# BS2X register map
File version: 0.1
CPU: other r0p0, little endian, MPU, FPU, 3 interrupt priority bits
Registers are 32-bit, read-write, reset 0x0 unless marked. A register's access mark holds for its fields unless they carry their own. Offsets are from the block's base; [hi:lo] are bit positions.

## USB — USB 2.0 OTG controller (Synopsys DWC OTG, device-controller base)
Base 0x58000000
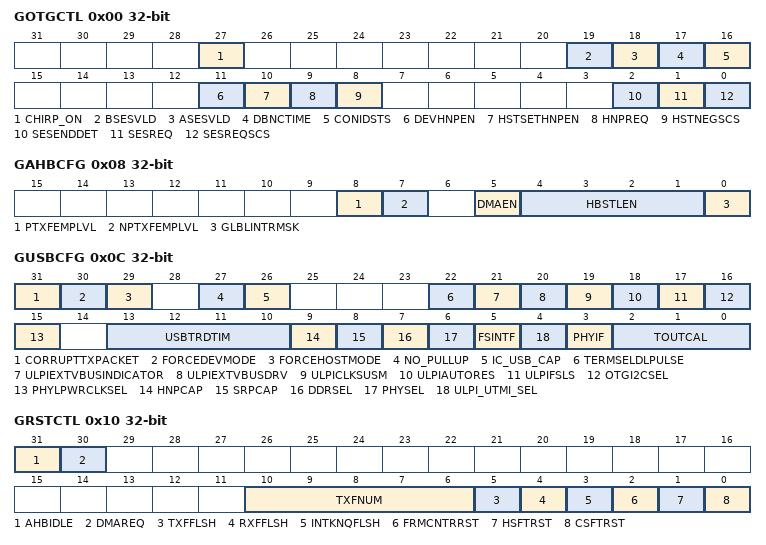
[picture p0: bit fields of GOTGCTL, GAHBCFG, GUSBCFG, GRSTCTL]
0x00 GOTGCTL — DOTG_GOTGCTL
  [27] CHIRP_ON, [19] BSESVLD, [18] ASESVLD, [17] DBNCTIME, [16] CONIDSTS, [11] DEVHNPEN, [10] HSTSETHNPEN, [9] HNPREQ, [8] HSTNEGSCS, [2] SESENDDET, [1] SESREQ, [0] SESREQSCS
0x04 GOTGINT — DOTG_GOTGINT
0x08 GAHBCFG — DOTG_GAHBCFG
  [8] PTXFEMPLVL, [7] NPTXFEMPLVL, [5] DMAEN, [4:1] HBSTLEN, [0] GLBLINTRMSK
0x0C GUSBCFG — DOTG_GUSBCFG
  [31] CORRUPTTXPACKET, [30] FORCEDEVMODE, [29] FORCEHOSTMODE, [27] NO_PULLUP, [26] IC_USB_CAP, [22] TERMSELDLPULSE, [21] ULPIEXTVBUSINDICATOR, [20] ULPIEXTVBUSDRV, [19] ULPICLKSUSM, [18] ULPIAUTORES, [17] ULPIFSLS, [16] OTGI2CSEL, [15] PHYLPWRCLKSEL, [13:10] USBTRDTIM, [9] HNPCAP, [8] SRPCAP, [7] DDRSEL, [6] PHYSEL, [5] FSINTF, [4] ULPI_UTMI_SEL, [3] PHYIF, [2:0] TOUTCAL
0x10 GRSTCTL — DOTG_GRSTCTL
  [31] AHBIDLE, [30] DMAREQ, [10:6] TXFNUM, [5] TXFFLSH, [4] RXFFLSH, [3] INTKNQFLSH, [2] FRMCNTRRST, [1] HSFTRST, [0] CSFTRST
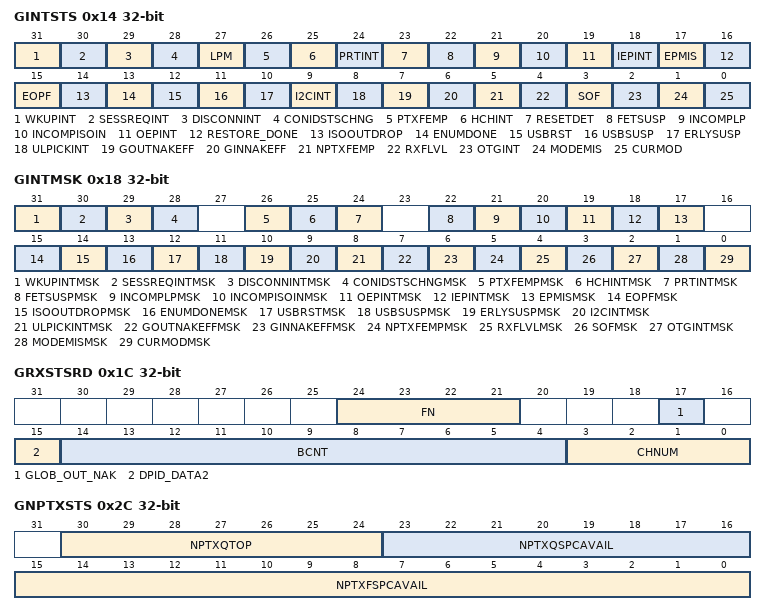
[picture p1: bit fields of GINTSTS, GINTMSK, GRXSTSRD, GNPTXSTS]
0x14 GINTSTS — DOTG_GINTSTS
  [31] WKUPINT, [30] SESSREQINT, [29] DISCONNINT, [28] CONIDSTSCHNG, [27] LPM, [26] PTXFEMP, [25] HCHINT, [24] PRTINT, [23] RESETDET, [22] FETSUSP, [21] INCOMPLP, [20] INCOMPISOIN, [19] OEPINT, [18] IEPINT, [17] EPMIS, [16] RESTORE_DONE, [15] EOPF, [14] ISOOUTDROP, [13] ENUMDONE, [12] USBRST, [11] USBSUSP, [10] ERLYSUSP, [9] I2CINT, [8] ULPICKINT, [7] GOUTNAKEFF, [6] GINNAKEFF, [5] NPTXFEMP, [4] RXFLVL, [3] SOF, [2] OTGINT, [1] MODEMIS, [0] CURMOD
0x18 GINTMSK — DOTG_GINTMSK
  [31] WKUPINTMSK, [30] SESSREQINTMSK, [29] DISCONNINTMSK, [28] CONIDSTSCHNGMSK, [26] PTXFEMPMSK, [25] HCHINTMSK, [24] PRTINTMSK, [22] FETSUSPMSK, [21] INCOMPLPMSK, [20] INCOMPISOINMSK, [19] OEPINTMSK, [18] IEPINTMSK, [17] EPMISMSK, [15] EOPFMSK, [14] ISOOUTDROPMSK, [13] ENUMDONEMSK, [12] USBRSTMSK, [11] USBSUSPMSK, [10] ERLYSUSPMSK, [9] I2CINTMSK, [8] ULPICKINTMSK, [7] GOUTNAKEFFMSK, [6] GINNAKEFFMSK, [5] NPTXFEMPMSK, [4] RXFLVLMSK, [3] SOFMSK, [2] OTGINTMSK, [1] MODEMISMSK, [0] CURMODMSK
0x1C GRXSTSRD — DOTG_GRXSTSRD
  [24:21] FN, [17] GLOB_OUT_NAK, [15] DPID_DATA2, [14:4] BCNT, [3:0] CHNUM
0x20 GRXSTSPD — DOTG_GRXSTSPD
0x24 GRXFSIZ — DOTG_GRXFSIZ
  [15:0] RXFDEP
0x28 GNPTXFSIZ — DOTG_GNPTXFSIZ
  [15:0] NPTXFDEP
0x2C GNPTXSTS — DOTG_GNPTXSTS
  [30:24] NPTXQTOP, [23:16] NPTXQSPCAVAIL, [15:0] NPTXFSPCAVAIL
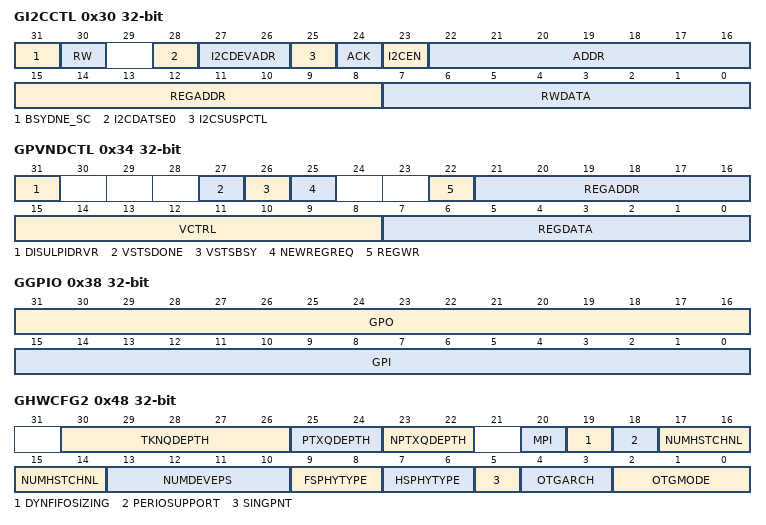
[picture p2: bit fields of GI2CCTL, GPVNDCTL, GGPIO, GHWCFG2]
0x30 GI2CCTL — DOTG_GI2CCTL
  [31] BSYDNE_SC, [30] RW, [28] I2CDATSE0, [27:26] I2CDEVADR, [25] I2CSUSPCTL, [24] ACK, [23] I2CEN, [22:16] ADDR, [15:8] REGADDR, [7:0] RWDATA
0x34 GPVNDCTL — DOTG_GPVNDCTL
  [31] DISULPIDRVR, [27] VSTSDONE, [26] VSTSBSY, [25] NEWREGREQ, [22] REGWR, [21:16] REGADDR, [15:8] VCTRL, [7:0] REGDATA
0x38 GGPIO — DOTG_GGPIO
  [31:16] GPO, [15:0] GPI
0x3C GUID — DOTG_GUID
0x40 GSNPSID — DOTG_GSNPSID
0x44 GHWCFG1 — DOTG_GHWCFG1
0x48 GHWCFG2 — DOTG_GHWCFG2
  [30:26] TKNQDEPTH, [25:24] PTXQDEPTH, [23:22] NPTXQDEPTH, [20] MPI, [19] DYNFIFOSIZING, [18] PERIOSUPPORT, [17:14] NUMHSTCHNL, [13:10] NUMDEVEPS, [9:8] FSPHYTYPE, [7:6] HSPHYTYPE, [5] SINGPNT, [4:3] OTGARCH, [2:0] OTGMODE
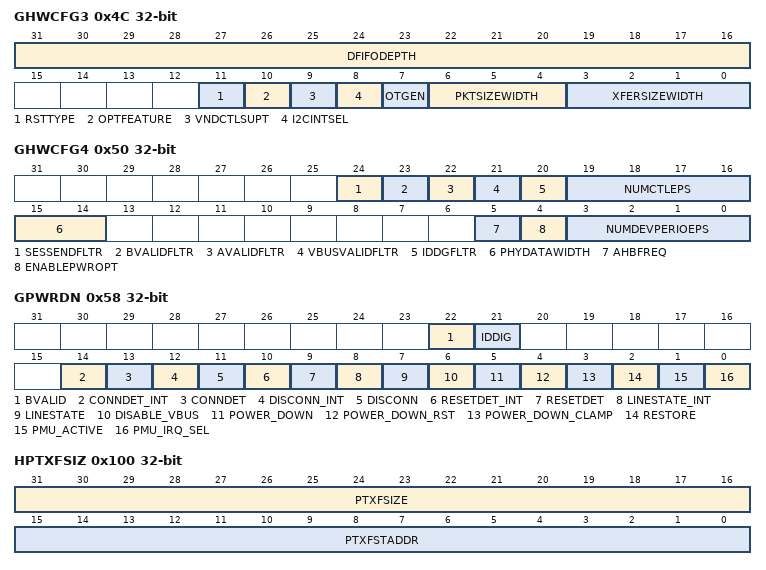
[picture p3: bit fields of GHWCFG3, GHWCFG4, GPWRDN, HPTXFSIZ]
0x4C GHWCFG3 — DOTG_GHWCFG3
  [31:16] DFIFODEPTH, [11] RSTTYPE, [10] OPTFEATURE, [9] VNDCTLSUPT, [8] I2CINTSEL, [7] OTGEN, [6:4] PKTSIZEWIDTH, [3:0] XFERSIZEWIDTH
0x50 GHWCFG4 — DOTG_GHWCFG4
  [24] SESSENDFLTR, [23] BVALIDFLTR, [22] AVALIDFLTR, [21] VBUSVALIDFLTR, [20] IDDGFLTR, [19:16] NUMCTLEPS, [15:14] PHYDATAWIDTH, [5] AHBFREQ, [4] ENABLEPWROPT, [3:0] NUMDEVPERIOEPS
0x54 GLPMCFG — DOTG_GLPMCFG
  [30] HSIC_CONN
0x58 GPWRDN — DOTG_GPWRDN
  [22] BVALID, [21] IDDIG, [14] CONNDET_INT, [13] CONNDET, [12] DISCONN_INT, [11] DISCONN, [10] RESETDET_INT, [9] RESETDET, [8] LINESTATE_INT, [7] LINESTATE, [6] DISABLE_VBUS, [5] POWER_DOWN, [4] POWER_DOWN_RST, [3] POWER_DOWN_CLAMP, [2] RESTORE, [1] PMU_ACTIVE, [0] PMU_IRQ_SEL
0x5C GDFIFOCFG — DOTG_GDFIFOCFG
0x60 GADPCTL — DOTG_GADPCTL
0x100 HPTXFSIZ — DOTG_HPTXFSIZ
  [31:16] PTXFSIZE, [15:0] PTXFSTADDR
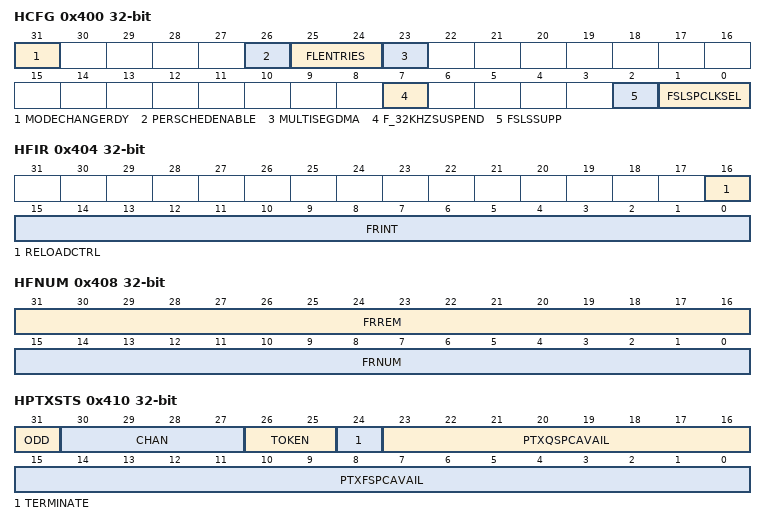
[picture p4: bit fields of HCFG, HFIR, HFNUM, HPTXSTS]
0x400 HCFG — DOTG_HCFG
  [31] MODECHANGERDY, [26] PERSCHEDENABLE, [25:24] FLENTRIES, [23] MULTISEGDMA, [7] F_32KHZSUSPEND, [2] FSLSSUPP, [1:0] FSLSPCLKSEL
0x404 HFIR — DOTG_HFIR
  [16] RELOADCTRL, [15:0] FRINT
0x408 HFNUM — DOTG_HFNUM
  [31:16] FRREM, [15:0] FRNUM
0x410 HPTXSTS — DOTG_HPTXSTS
  [31] ODD, [30:27] CHAN, [26:25] TOKEN, [24] TERMINATE, [23:16] PTXQSPCAVAIL, [15:0] PTXFSPCAVAIL
0x414 HAINT — DOTG_HAINT
  [15:0] HAINT
0x418 HAINTMSK — DOTG_HAINTMSK
  [15:0] HAINTMSK
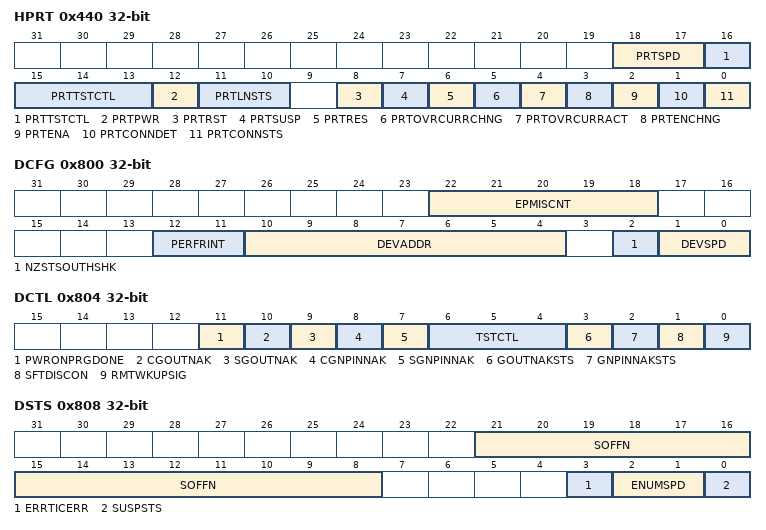
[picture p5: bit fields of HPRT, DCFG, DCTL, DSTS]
0x440 HPRT — DOTG_HPRT
  [18:17] PRTSPD, [16:13] PRTTSTCTL, [12] PRTPWR, [11:10] PRTLNSTS, [8] PRTRST, [7] PRTSUSP, [6] PRTRES, [5] PRTOVRCURRCHNG, [4] PRTOVRCURRACT, [3] PRTENCHNG, [2] PRTENA, [1] PRTCONNDET, [0] PRTCONNSTS
0x800 DCFG — DOTG_DCFG
  [22:18] EPMISCNT, [12:11] PERFRINT, [10:4] DEVADDR, [2] NZSTSOUTHSHK, [1:0] DEVSPD
0x804 DCTL — DOTG_DCTL
  [11] PWRONPRGDONE, [10] CGOUTNAK, [9] SGOUTNAK, [8] CGNPINNAK, [7] SGNPINNAK, [6:4] TSTCTL, [3] GOUTNAKSTS, [2] GNPINNAKSTS, [1] SFTDISCON, [0] RMTWKUPSIG
0x808 DSTS — DOTG_DSTS
  [21:8] SOFFN, [3] ERRTICERR, [2:1] ENUMSPD, [0] SUSPSTS
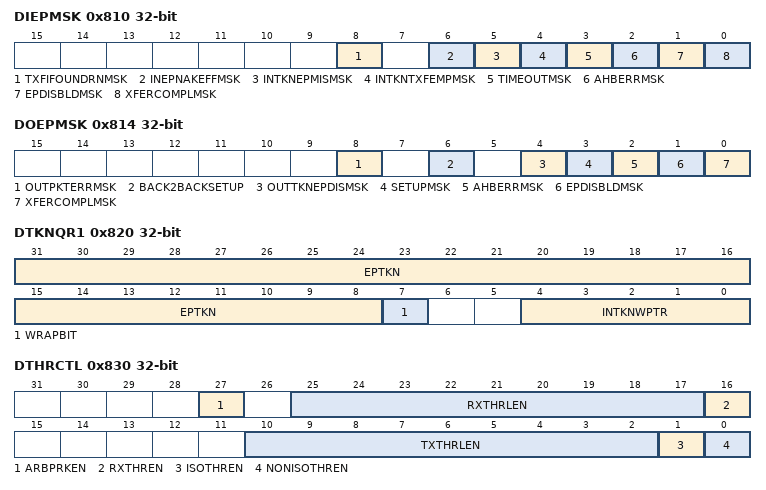
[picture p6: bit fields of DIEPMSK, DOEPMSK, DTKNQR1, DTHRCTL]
0x810 DIEPMSK — DOTG_DIEPMSK
  [8] TXFIFOUNDRNMSK, [6] INEPNAKEFFMSK, [5] INTKNEPMISMSK, [4] INTKNTXFEMPMSK, [3] TIMEOUTMSK, [2] AHBERRMSK, [1] EPDISBLDMSK, [0] XFERCOMPLMSK
0x814 DOEPMSK — DOTG_DOEPMSK
  [8] OUTPKTERRMSK, [6] BACK2BACKSETUP, [4] OUTTKNEPDISMSK, [3] SETUPMSK, [2] AHBERRMSK, [1] EPDISBLDMSK, [0] XFERCOMPLMSK
0x818 DAINT — DOTG_DAINT
  [15:0] INEPINT
0x81C DAINTMSK — DOTG_DAINTMSK
  [15:0] INEPINT
0x820 DTKNQR1 — DOTG_DTKNQR1
  [31:8] EPTKN, [7] WRAPBIT, [4:0] INTKNWPTR
0x824 DTKNQR2 — DOTG_DTKNQR2
0x828 DVBUSDIS — DOTG_DVBUSDIS
  [15:0] DVBUSDIS
0x82C DVBUSPULSE — DOTG_DVBUSPULSE
  [11:0] DVBUSPULSE
0x830 DTHRCTL — DOTG_DTHRCTL
  [27] ARBPRKEN, [25:17] RXTHRLEN, [16] RXTHREN, [10:2] TXTHRLEN, [1] ISOTHREN, [0] NONISOTHREN
0x834 DTKNQR4 — DOTG_DTKNQR4
0x838 DEACHINT — DOTG_DEACHINT
0x83C DEACHINTMSK — DOTG_DEACHINTMSK
0xE00 PCGCCTL — DOTG_PCGCCTL
